# HC32M458 register map
File version: 1.0
CPU: CM4 r0p1, little endian, MPU, FPU, 4 interrupt priority bits
Registers are 16-bit, read-write, reset 0x0 unless marked. A register's access mark holds for its fields unless they carry their own. Offsets are from the block's base; [hi:lo] are bit positions; {n}, {i} and the like mark numbered series; 'fields as' and 'values as' point back to an identical list.

## EFM
Base 0x40010400
0x00 FAPRT 32-bit
  [15:0] FAPRT
0x04 FSTP 32-bit
  [0] FSTP
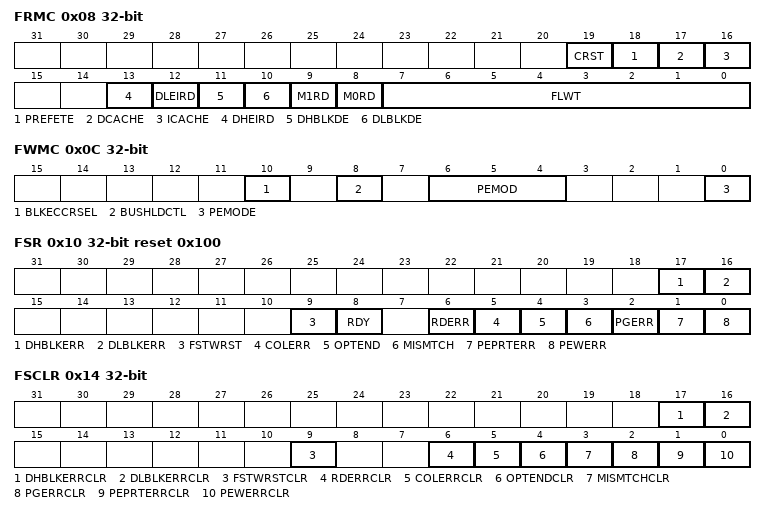
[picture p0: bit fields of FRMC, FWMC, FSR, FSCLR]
0x08 FRMC 32-bit
  [19] CRST, [18] PREFETE, [17] DCACHE, [16] ICACHE, [13] DHEIRD, [12] DLEIRD, [11] DHBLKDE, [10] DLBLKDE, [9] M1RD, [8] M0RD, [7:0] FLWT
0x0C FWMC 32-bit
  [10] BLKECCRSEL, [8] BUSHLDCTL, [6:4] PEMOD, [0] PEMODE
0x10 FSR 32-bit reset 0x100
  [17] DHBLKERR, [16] DLBLKERR, [9] FSTWRST, [8] RDY ro, [6] RDERR ro, [5] COLERR ro, [4] OPTEND ro, [3] MISMTCH ro, [2] PGERR, [1] PEPRTERR ro, [0] PEWERR ro
0x14 FSCLR 32-bit
  [17] DHBLKERRCLR, [16] DLBLKERRCLR, [9] FSTWRSTCLR, [6] RDERRCLR, [5] COLERRCLR, [4] OPTENDCLR, [3] MISMTCHCLR, [2] PGERRCLR, [1] PEPRTERRCLR, [0] PEWERRCLR
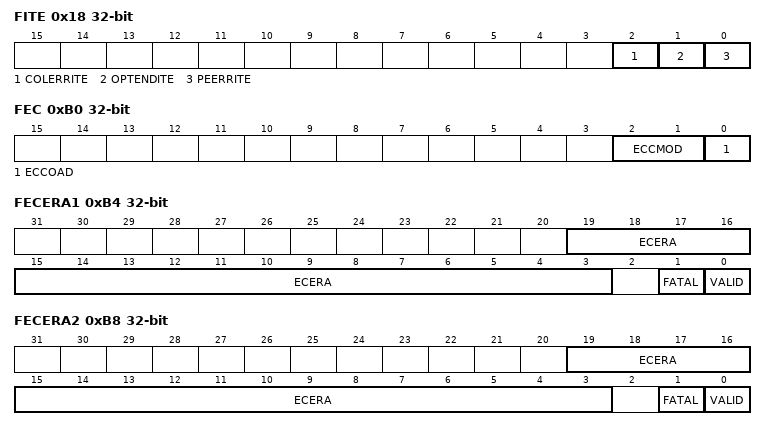
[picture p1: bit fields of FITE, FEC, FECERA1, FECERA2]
0x18 FITE 32-bit
  [2] COLERRITE, [1] OPTENDITE, [0] PEERRITE
0x20 FPMTSW 32-bit
  [18:0] FPMTSW
0x24 FPMTEW 32-bit
  [18:0] FPMTEW
{0x50+4i} UQID{i} 32-bit ro (i=0..2)
0x70 FOCDPRTFG 32-bit ro
  [3] PCROPST
0xB0 FEC 32-bit
  [2:1] ECCMOD, [0] ECCOAD
0xB4 FECERA1 32-bit
  [19:3] ECERA, [1] FATAL, [0] VALID
0xB8 FECERA2 32-bit
  [19:3] ECERA, [1] FATAL, [0] VALID
0xBC ERI0 32-bit
0xC0 ERI1 32-bit
0xC4 ERI2 32-bit
  [7:0] ERI2
0x120 FCRCDOR 32-bit ro
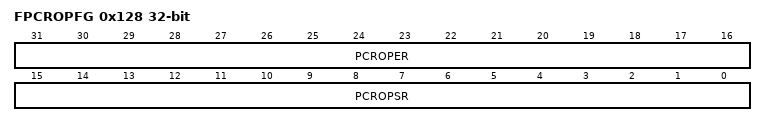
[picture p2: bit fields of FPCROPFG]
0x128 FPCROPFG 32-bit ro
  [31:16] PCROPER, [15:0] PCROPSR
0x288 HRCCFGR 8-bit
  [2:0] HRCFREQS

## EFM2
Base 0x01001C50
{0x0+4i} PN{i} 32-bit ro (i=0..3)

## EMB0 — desc EMB
Base 0x40017C00
Same registers: EMB1 0x40017C20
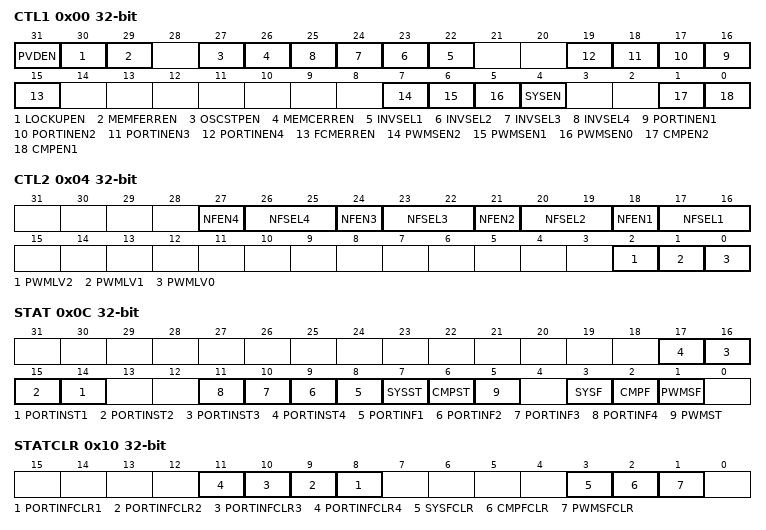
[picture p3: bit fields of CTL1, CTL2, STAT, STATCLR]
0x00 CTL1 32-bit
  [31] PVDEN, [30] LOCKUPEN, [29] MEMFERREN, [27] OSCSTPEN, [26] MEMCERREN, [n+21] INVSEL{n} (n=1..4), [n+15] PORTINEN{n} (n=1..4), [15] FCMERREN, [7] PWMSEN2, [6] PWMSEN1, [5] PWMSEN0, [4] SYSEN, [1] CMPEN2, [0] CMPEN1
0x04 CTL2 32-bit
  [3n+15] NFEN{n} (n=1..4), [3n+14:3n+13] NFSEL{n} (n=1..4), [2] PWMLV2, [1] PWMLV1, [0] PWMLV0
0x08 SOE 32-bit
  [0] SOE
0x0C STAT 32-bit ro
  [n+13] PORTINST{n} (n=1..4), [n+7] PORTINF{n} (n=1..4), [7] SYSST, [6] CMPST, [5] PWMST, [3] SYSF, [2] CMPF, [1] PWMSF
0x10 STATCLR 32-bit wo
  [n+7] PORTINFCLR{n} (n=1..4), [3] SYSFCLR, [2] CMPFCLR, [1] PWMSFCLR
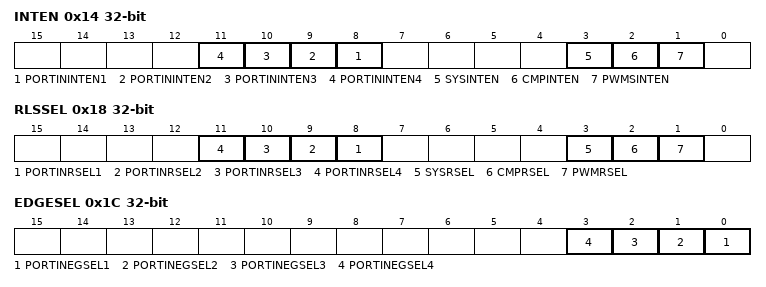
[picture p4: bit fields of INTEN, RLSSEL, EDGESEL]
0x14 INTEN 32-bit
  [n+7] PORTININTEN{n} (n=1..4), [3] SYSINTEN, [2] CMPINTEN, [1] PWMSINTEN
0x18 RLSSEL 32-bit
  [n+7] PORTINRSEL{n} (n=1..4), [3] SYSRSEL, [2] CMPRSEL, [1] PWMRSEL
0x1C EDGESEL 32-bit
  [n-1] PORTINEGSEL{n} (n=1..4)

## EMB2 — desc EMB
Base 0x40017C40
Same registers: EMB3 0x40017C60
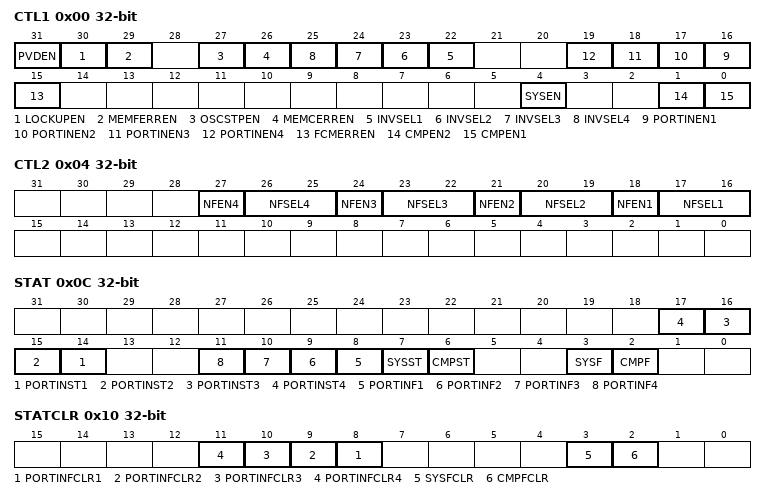
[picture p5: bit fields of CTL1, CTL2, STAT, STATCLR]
0x00 CTL1 32-bit
  [31] PVDEN, [30] LOCKUPEN, [29] MEMFERREN, [27] OSCSTPEN, [26] MEMCERREN, [n+21] INVSEL{n} (n=1..4), [n+15] PORTINEN{n} (n=1..4), [15] FCMERREN, [4] SYSEN, [1] CMPEN2, [0] CMPEN1
0x04 CTL2 32-bit
  [3n+15] NFEN{n} (n=1..4), [3n+14:3n+13] NFSEL{n} (n=1..4)
0x08 SOE 32-bit
  [0] SOE
0x0C STAT 32-bit ro
  [n+13] PORTINST{n} (n=1..4), [n+7] PORTINF{n} (n=1..4), [7] SYSST, [6] CMPST, [3] SYSF, [2] CMPF
0x10 STATCLR 32-bit wo
  [n+7] PORTINFCLR{n} (n=1..4), [3] SYSFCLR, [2] CMPFCLR
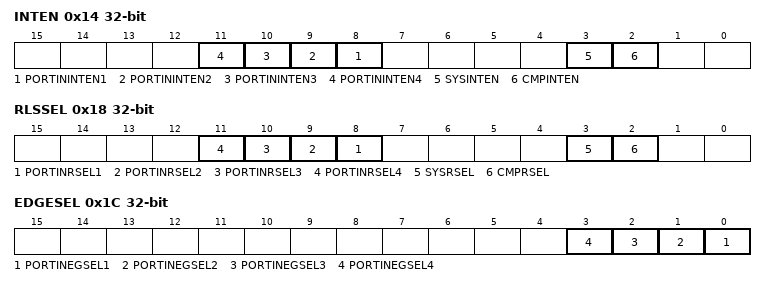
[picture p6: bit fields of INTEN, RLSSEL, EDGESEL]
0x14 INTEN 32-bit
  [n+7] PORTININTEN{n} (n=1..4), [3] SYSINTEN, [2] CMPINTEN
0x18 RLSSEL 32-bit
  [n+7] PORTINRSEL{n} (n=1..4), [3] SYSRSEL, [2] CMPRSEL
0x1C EDGESEL 32-bit
  [n-1] PORTINEGSEL{n} (n=1..4)

## FCM
Base 0x40048400
0x00 LVR 32-bit
  [15:0] LVR
0x04 UVR 32-bit
  [15:0] UVR
0x08 CNTR 32-bit ro
  [15:0] CNTR
0x0C STR 32-bit
  [0] START
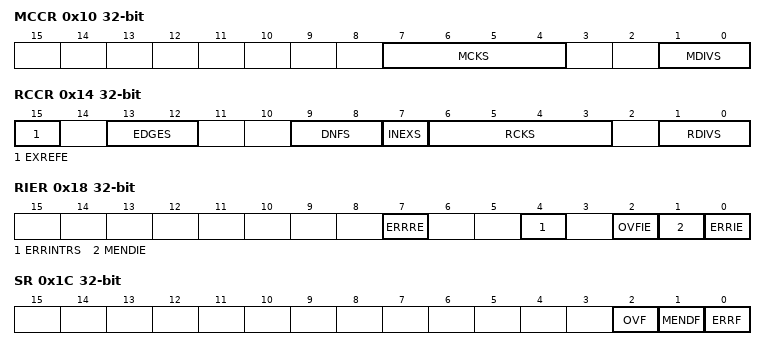
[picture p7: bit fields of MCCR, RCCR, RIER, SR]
0x10 MCCR 32-bit
  [7:4] MCKS, [1:0] MDIVS
0x14 RCCR 32-bit
  [15] EXREFE, [13:12] EDGES, [9:8] DNFS, [7] INEXS, [6:3] RCKS, [1:0] RDIVS
0x18 RIER 32-bit
  [7] ERRRE, [4] ERRINTRS, [2] OVFIE, [1] MENDIE, [0] ERRIE
0x1C SR 32-bit ro
  [2] OVF, [1] MENDF, [0] ERRF
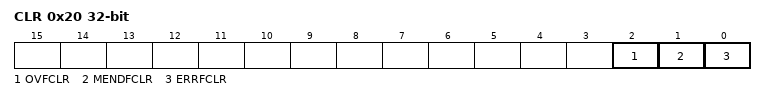
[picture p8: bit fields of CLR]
0x20 CLR 32-bit wo
  [2] OVFCLR, [1] MENDFCLR, [0] ERRFCLR

## GPIO
Base 0x40053800
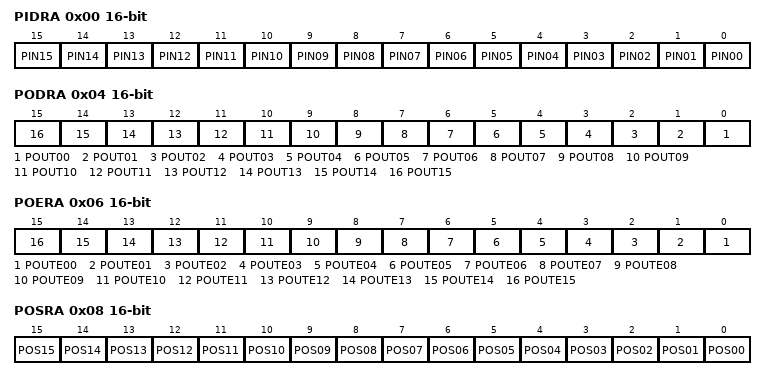
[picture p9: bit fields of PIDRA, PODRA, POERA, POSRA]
0x00 PIDRA ro
  [n] PIN{n:02} (n=0..15)
0x04 PODRA
  [n] POUT{n:02} (n=0..15)
0x06 POERA
  [n] POUTE{n:02} (n=0..15)
0x08 POSRA wo
  [n] POS{n:02} (n=0..15)
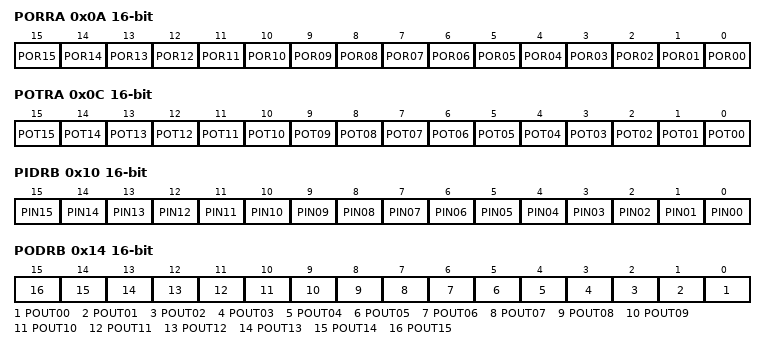
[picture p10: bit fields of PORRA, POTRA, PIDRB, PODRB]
0x0A PORRA wo
  [n] POR{n:02} (n=0..15)
0x0C POTRA wo
  [n] POT{n:02} (n=0..15)
0x10 PIDRB ro
  [n] PIN{n:02} (n=0..15)
0x14 PODRB
  [n] POUT{n:02} (n=0..15)
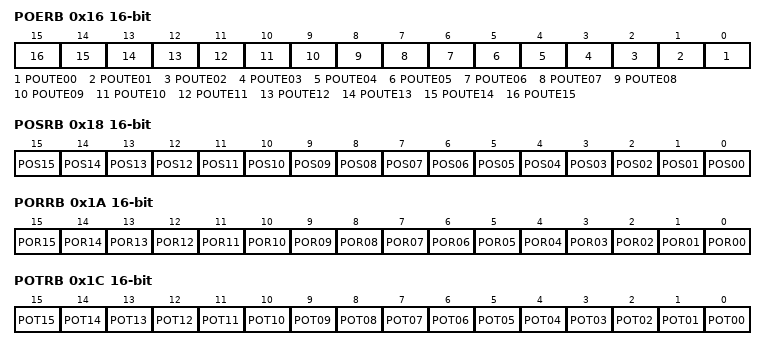
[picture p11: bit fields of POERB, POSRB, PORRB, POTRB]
0x16 POERB
  [n] POUTE{n:02} (n=0..15)
0x18 POSRB wo
  [n] POS{n:02} (n=0..15)
0x1A PORRB wo
  [n] POR{n:02} (n=0..15)
0x1C POTRB wo
  [n] POT{n:02} (n=0..15)
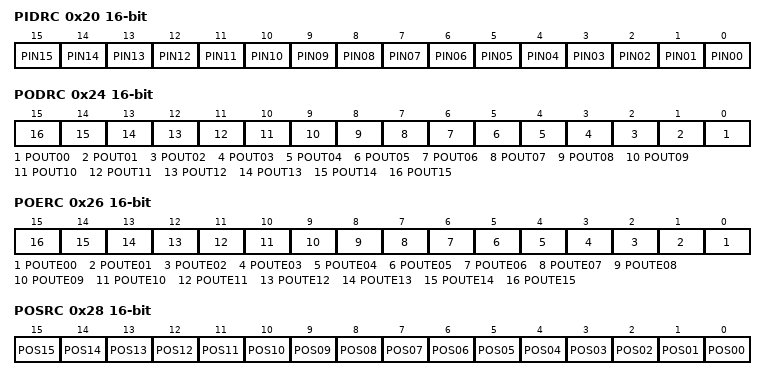
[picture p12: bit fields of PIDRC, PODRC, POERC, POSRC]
0x20 PIDRC ro
  [n] PIN{n:02} (n=0..15)
0x24 PODRC
  [n] POUT{n:02} (n=0..15)
0x26 POERC
  [n] POUTE{n:02} (n=0..15)
0x28 POSRC wo
  [n] POS{n:02} (n=0..15)
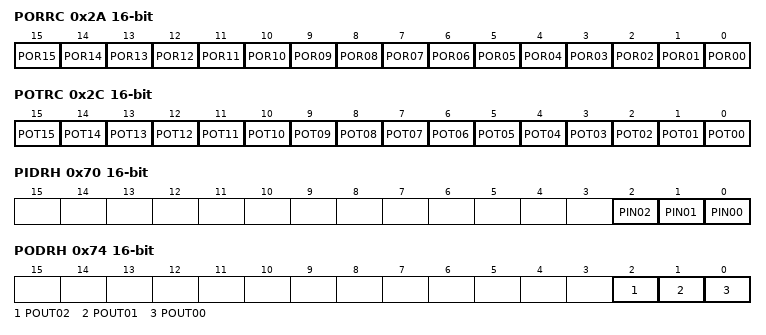
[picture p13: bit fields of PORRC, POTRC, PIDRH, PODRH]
0x2A PORRC wo
  [n] POR{n:02} (n=0..15)
0x2C POTRC wo
  [n] POT{n:02} (n=0..15)
0x30 PIDRD ro
  [2] PIN02
0x34 PODRD
  [2] POUT02
0x36 POERD
  [2] POUTE02
0x38 POSRD ro
  [2] POS02 wo
0x3A PORRD ro
  [2] POR02 wo
0x3C POTRD ro
  [2] POT02 wo
0x70 PIDRH ro
  [2] PIN02, [1] PIN01, [0] PIN00
0x74 PODRH
  [2] POUT02, [1] POUT01, [0] POUT00
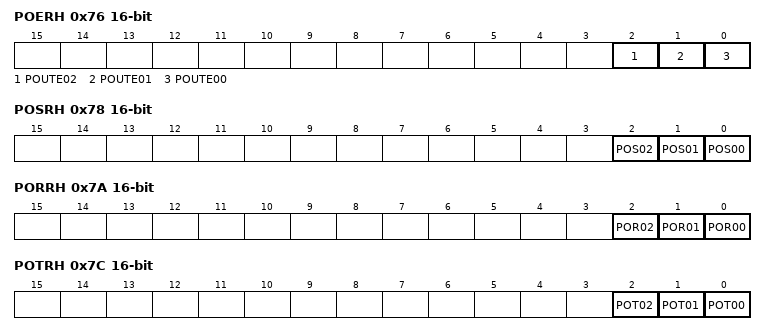
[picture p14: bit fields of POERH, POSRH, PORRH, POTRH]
0x76 POERH
  [2] POUTE02, [1] POUTE01, [0] POUTE00
0x78 POSRH wo
  [2] POS02, [1] POS01, [0] POS00
0x7A PORRH wo
  [2] POR02, [1] POR01, [0] POR00
0x7C POTRH wo
  [2] POT02, [1] POT01, [0] POT00
0x3F4 PSPCR reset 0x3
  [1:0] SPFE
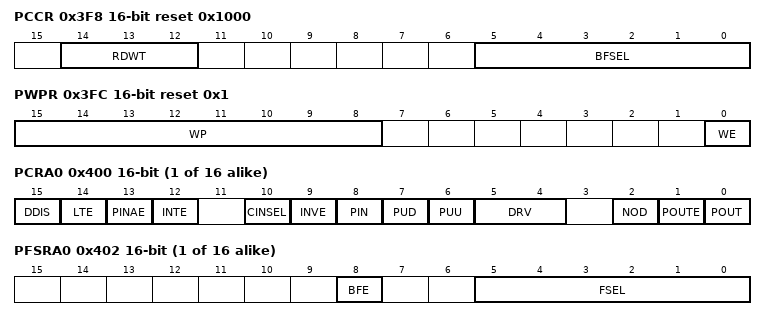
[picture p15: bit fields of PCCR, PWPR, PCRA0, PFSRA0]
0x3F8 PCCR reset 0x1000
  [14:12] RDWT, [5:0] BFSEL
0x3FC PWPR reset 0x1
  [15:8] WP wo, [0] WE
{0x400+4i} PCRA{i} (i=0..15)
  [15] DDIS, [14] LTE, [13] PINAE, [12] INTE, [10] CINSEL, [9] INVE, [8] PIN ro, [7] PUD, [6] PUU, [5:4] DRV, [2] NOD, [1] POUTE, [0] POUT
{0x402+4i} PFSRA{i} (i=0..15)
  [8] BFE, [5:0] FSEL
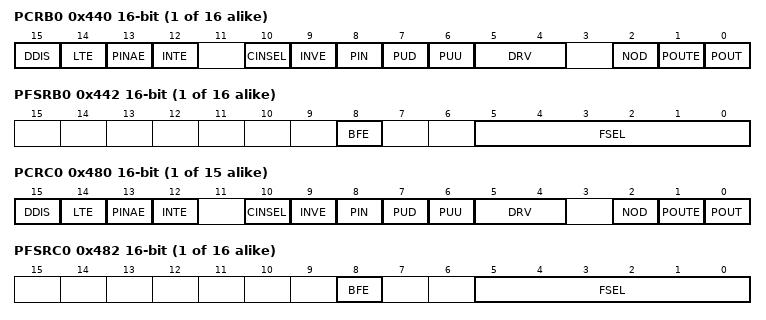
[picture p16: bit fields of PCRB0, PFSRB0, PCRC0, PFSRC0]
{0x440+4i} PCRB{i} (i=0..15)
  fields as PCRA0
{0x442+4i} PFSRB{i} (i=0..15)
  [8] BFE, [5:0] FSEL
{0x480+4i} PCRC{i} (i=0..14)
  fields as PCRA0
{0x482+4i} PFSRC{i} (i=0..15)
  [8] BFE, [5:0] FSEL
0x4BC PCRC15 reset 0x8100
  fields as PCRA0
0x4C8 PCRD2
  fields as PCRA0
0x4CA PFSRD2
  [8] BFE, [5:0] FSEL
{0x5C0+4i} PCRH{i} (i=0..2)
  fields as PCRA0
{0x5C2+4i} PFSRH{i} (i=0..2)
  [8] BFE, [5:0] FSEL
